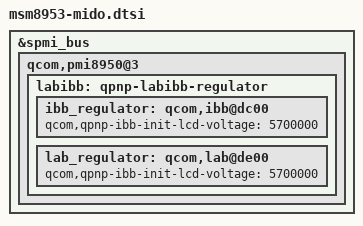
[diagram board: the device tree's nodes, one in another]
/*
 * Copyright (c) 2017, The Linux Foundation. All rights reserved.
 *
 * This program is free software; you can redistribute it and/or modify
 * it under the terms of the GNU General Public License version 2 and
 * only version 2 as published by the Free Software Foundation.
 *
 * This program is distributed in the hope that it will be useful,
 * but WITHOUT ANY WARRANTY; without even the implied warranty of
 * MERCHANTABILITY or FITNESS FOR A PARTICULAR PURPOSE.  See the
 * GNU General Public License for more details.
 */

#include "msm-audio-mido.dtsi"
#include "msm8953-general-mido.dtsi"
#include "msm8953-display-mido.dtsi"
#include "msm8953-camera-sensor-qrd-mido.dtsi"
#include "msm8953-pinctrl-mido.dtsi"
#include "msm8953-memory-mido.dtsi"

&spmi_bus {
	qcom,pmi8950@3 {
		labibb: qpnp-labibb-regulator {
			status = "ok";
			ibb_regulator: qcom,ibb@dc00 {
				/delete-property/
					qcom,qpnp-ibb-use-default-voltage;
				qcom,qpnp-ibb-init-lcd-voltage = <5700000>;
			};

			lab_regulator: qcom,lab@de00 {
				/delete-property/
					qcom,qpnp-ibb-use-default-voltage;
				qcom,qpnp-ibb-init-lcd-voltage = <5700000>;
			};
		};
	};
};
